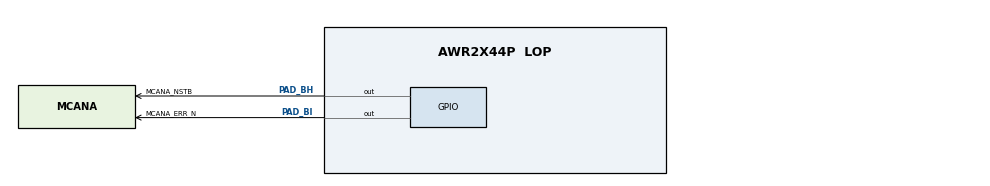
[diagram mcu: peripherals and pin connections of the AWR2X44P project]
/**
 * @cliArgs --device "AWR2X44P" --part "Default" --package "LOP" --context "r5fss0-0" --product "MCU_PLUS_SDK_AWR2X44P@10.00.00"
 * @versions {"tool":"1.25.0+4268"}
 */

/**
 * Import the modules used in this configuration.
 */
const flash      = scripting.addModule("/board/flash/flash", {}, false);
const flash1     = flash.addInstance();
const adcbuf     = scripting.addModule("/drivers/adcbuf/adcbuf", {}, false);
const adcbuf1    = adcbuf.addInstance();
const cbuff      = scripting.addModule("/drivers/cbuff/cbuff", {}, false);
const cbuff1     = cbuff.addInstance();
const crc        = scripting.addModule("/drivers/crc/crc", {}, false);
const crc1       = crc.addInstance();
const edma       = scripting.addModule("/drivers/edma/edma", {}, false);
const edma1      = edma.addInstance();
const edma2      = edma.addInstance();
const gpadc      = scripting.addModule("/drivers/gpadc/gpadc", {}, false);
const gpadc1     = gpadc.addInstance();
const gpio       = scripting.addModule("/drivers/gpio/gpio", {}, false);
const gpio1      = gpio.addInstance();
const gpio2      = gpio.addInstance();
const ipc        = scripting.addModule("/drivers/ipc/ipc");
const mcan       = scripting.addModule("/drivers/mcan/mcan");
const mcan1      = mcan.addInstance();
const mcan2      = mcan.addInstance();
const mibspi     = scripting.addModule("/drivers/mibspi/mibspi", {}, false);
const mibspi1    = mibspi.addInstance();
const uart       = scripting.addModule("/drivers/uart/uart", {}, false);
const uart1      = uart.addInstance();
const uart2      = uart.addInstance();
const clock      = scripting.addModule("/kernel/dpl/clock");
const debug_log  = scripting.addModule("/kernel/dpl/debug_log");
const mpu_armv7  = scripting.addModule("/kernel/dpl/mpu_armv7", {}, false);
const mpu_armv71 = mpu_armv7.addInstance();
const mpu_armv72 = mpu_armv7.addInstance();
const mpu_armv73 = mpu_armv7.addInstance();
const mpu_armv74 = mpu_armv7.addInstance();
const mpu_armv75 = mpu_armv7.addInstance();
const mpu_armv76 = mpu_armv7.addInstance();
const mpu_armv77 = mpu_armv7.addInstance();

/**
 * Write custom configuration values to the imported modules.
 */
flash1.$name                  = "CONFIG_FLASH0";
flash1.device                 = "CUSTOM_FLASH";
flash1.fname                  = "W25Q32JV";
flash1.flashSize              = 4194304;
flash1.flashManfId            = "0xEF";
flash1.flashDeviceId          = "0x4016";
flash1.peripheralDriver.$name = "CONFIG_QSPI0";

adcbuf1.$name = "CONFIG_ADCBUF0";

cbuff1.$name = "CONFIG_CBUFF0";

crc1.$name = "CONFIG_CRC0";

edma1.$name                             = "CONFIG_EDMA0";
edma1.instance                          = "EDMA_DSS_B";
edma1.regionId                          = 0;
cbuff1.edmaConfig                       = edma1;
edma1.edmaRmDmaCh[0].resourceType       = scripting.forceWrite("ownDmaCh");
edma1.edmaRmDmaCh[0].$name              = "CONFIG_EDMA_RM0";
edma1.edmaRmDmaCh[0].startIndex         = 0;
edma1.edmaRmDmaCh[0].endIndex           = 63;
edma1.edmaRmQdmaCh[0].$name             = "CONFIG_EDMA_RM1";
edma1.edmaRmTcc[0].$name                = "CONFIG_EDMA_RM2";
edma1.edmaRmTcc[0].startIndex           = 0;
edma1.edmaRmTcc[0].endIndex             = 63;
edma1.edmaRmParam[0].$name              = "CONFIG_EDMA_RM3";
edma1.edmaRmParam[0].startIndex         = 0;
edma1.edmaRmReservedDmaCh[0].$name      = "CONFIG_EDMA_RM4";
edma1.edmaRmReservedDmaCh[0].startIndex = 0;
edma1.edmaRmReservedDmaCh[0].endIndex   = 0;

gpadc1.$name                          = "CONFIG_GPADC0";
gpadc1.readMode                       = "SINGLE";
gpadc1.gpadcChannel.create(5);
gpadc1.gpadcChannel[0].$name          = "CONFIG_GPADC_CH0";
gpadc1.gpadcChannel[0].isBufferedMode = "TRUE";
gpadc1.gpadcChannel[0].useLuTable     = "FALSE";
gpadc1.gpadcChannel[1].$name          = "CONFIG_GPADC_CH1";
gpadc1.gpadcChannel[1].ChannelIndex   = 2;
gpadc1.gpadcChannel[1].isBufferedMode = "TRUE";
gpadc1.gpadcChannel[1].useLuTable     = "FALSE";
gpadc1.gpadcChannel[2].$name          = "CONFIG_GPADC_CH2";
gpadc1.gpadcChannel[2].ChannelIndex   = 3;
gpadc1.gpadcChannel[2].isBufferedMode = "TRUE";
gpadc1.gpadcChannel[2].useLuTable     = "FALSE";
gpadc1.gpadcChannel[3].$name          = "CONFIG_GPADC_CH3";
gpadc1.gpadcChannel[3].ChannelIndex   = 6;
gpadc1.gpadcChannel[4].$name          = "CONFIG_GPADC_CH4";
gpadc1.gpadcChannel[4].ChannelIndex   = 5;

gpio1.$name                = "MCANA_ERR_N";
gpio1.GPIO.$assign         = "GPIO9";
gpio1.GPIO.gpioPin.$assign = "PAD_BI";

gpio2.$name                = "MCANA_NSTB";
gpio2.pinDir               = "OUTPUT";
gpio2.GPIO.$assign         = "GPIO8";
gpio2.GPIO.gpioPin.$assign = "PAD_BH";

ipc.vringNumBuf  = 1;
ipc.vringMsgSize = 1152;

mcan.nomTimeSeg1       = 30;
mcan.nomTimeSeg2       = 7;
mcan.dataRatePrescalar = 7;
mcan.dataTimeSeg1      = 2;

mcan1.$name           = "CONFIG_MCAN0";
mcan1.MCAN.$assign    = "MCANA";
mcan1.MCAN.RX.$assign = "PAD_BO";
mcan1.MCAN.TX.$assign = "PAD_BN";

mcan2.$name           = "CONFIG_MCAN1";
mcan2.MCAN.$assign    = "MCANB";
mcan2.MCAN.RX.$assign = "PAD_BS";
mcan2.MCAN.TX.$assign = "PAD_BR";

mibspi1.$name                  = "CONFIG_MIBSPI1";
mibspi1.t2cDelay               = 0x5;
mibspi1.c2tDelay               = 0x5;
mibspi1.dataSize               = 8;
mibspi1.frameFormat            = "POL0_PHA1";
mibspi1.advanced               = true;
mibspi1.csHold                 = true;
mibspi1.MIBSPI.$assign         = "MIBSPIA";
mibspi1.mibspiChannel[0].$name = "CONFIG_MIBSPI_CH0";

const edma3                        = edma.addInstance({}, false);
edma3.$name                        = "CONFIG_EDMA2";
mibspi1.edmaConfig                 = edma3;
edma3.edmaRmDmaCh[0].resourceType  = scripting.forceWrite("ownDmaCh");
edma3.edmaRmDmaCh[0].$name         = "CONFIG_EDMA_RM10";
edma3.edmaRmQdmaCh[0].$name        = "CONFIG_EDMA_RM11";
edma3.edmaRmTcc[0].$name           = "CONFIG_EDMA_RM12";
edma3.edmaRmParam[0].$name         = "CONFIG_EDMA_RM13";
edma3.edmaRmReservedDmaCh[0].$name = "CONFIG_EDMA_RM14";

uart1.$name           = "CONFIG_UART1";
uart1.intrEnable      = "DISABLE";
uart1.baudRate        = 3125000;
uart1.UART.$assign    = "UARTB";
uart1.UART.RX.$used   = false;
uart1.UART.TX.$assign = "PAD_DE";

uart2.$name           = "CONFIG_UART0";
uart2.UART.$assign    = "UARTA";
uart2.UART.RX.$assign = "PAD_DA";
uart2.UART.TX.$assign = "PAD_DB";

edma2.$name                        = "CONFIG_EDMA1";
flash1.peripheralDriver.edmaConfig = edma2;
uart1.edmaConfig                   = edma2;
uart2.edmaConfig                   = edma2;
edma2.edmaRmDmaCh[0].$name         = "CONFIG_EDMA_RM5";
edma2.edmaRmQdmaCh[0].$name        = "CONFIG_EDMA_RM6";
edma2.edmaRmTcc[0].$name           = "CONFIG_EDMA_RM7";
edma2.edmaRmParam[0].$name         = "CONFIG_EDMA_RM8";
edma2.edmaRmReservedDmaCh[0].$name = "CONFIG_EDMA_RM9";

debug_log.enableLogZoneError   = false;
debug_log.enableLogZoneWarning = false;

mpu_armv71.$name        = "CONFIG_MPU_REGION0";
mpu_armv71.attributes   = "Device";
mpu_armv71.allowExecute = false;

mpu_armv72.$name = "CONFIG_MPU_REGION1";
mpu_armv72.size  = 14;

mpu_armv73.$name    = "CONFIG_MPU_REGION2";
mpu_armv73.baseAddr = 0x80000;
mpu_armv73.size     = 14;

mpu_armv74.$name    = "CONFIG_MPU_REGION3";
mpu_armv74.baseAddr = 0x10200000;
mpu_armv74.size     = 20;

mpu_armv75.$name    = "CONFIG_MPU_REGION4";
mpu_armv75.size     = 14;
mpu_armv75.baseAddr = 0x10214000;

mpu_armv76.$name        = "CONFIG_MPU_REGION5";
mpu_armv76.baseAddr     = 0xC5000000;
mpu_armv76.size         = 13;
mpu_armv76.attributes   = "NonCached";
mpu_armv76.allowExecute = false;

mpu_armv77.$name        = "CONFIG_MPU_REGION6";
mpu_armv77.baseAddr     = 0x88000000;
mpu_armv77.allowExecute = false;
mpu_armv77.size         = 22;
mpu_armv77.attributes   = "NonCached";

/**
 * Pinmux solution for unlocked pins/peripherals. This ensures that minor changes to the automatic solver in a future
 * version of the tool will not impact the pinmux you originally saw.  These lines can be completely deleted in order to
 * re-solve from scratch.
 */
flash1.peripheralDriver.QSPI["0"].$suggestSolution = "PAD_AL";
flash1.peripheralDriver.QSPI["1"].$suggestSolution = "PAD_AM";
flash1.peripheralDriver.QSPI["2"].$suggestSolution = "PAD_AN";
flash1.peripheralDriver.QSPI["3"].$suggestSolution = "PAD_AO";
flash1.peripheralDriver.QSPI.$suggestSolution      = "QSPI0";
flash1.peripheralDriver.QSPI.CLK.$suggestSolution  = "PAD_AP";
flash1.peripheralDriver.QSPI.CS.$suggestSolution   = "PAD_AQ";
mibspi1.MIBSPI.CLK.$suggestSolution                = "PAD_CQ";
mibspi1.MIBSPI.MISO.$suggestSolution               = "PAD_CP";
mibspi1.MIBSPI.MOSI.$suggestSolution               = "PAD_CO";
mibspi1.mibspiChannel[0].MSS_CSn.$suggestSolution  = "PAD_CR";
